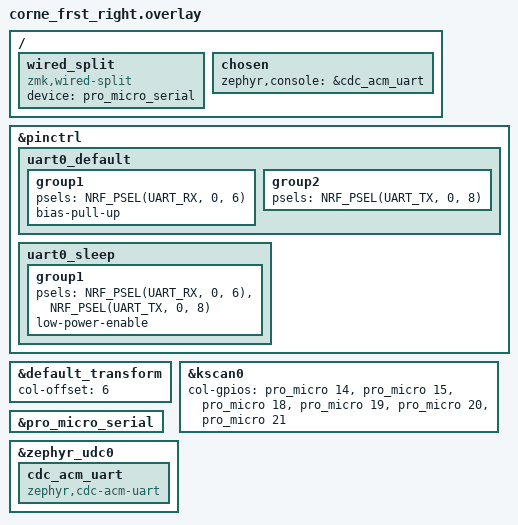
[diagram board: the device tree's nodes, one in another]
/*
 * Copyright (c) 2025 Jon Sharp
 * Co-authored by Claude (Anthropic)
 * SPDX-License-Identifier: MIT
 */

#include <dt-bindings/pinctrl/nrf-pinctrl.h>
#include "corne_frst.dtsi"

/*
 * Swap TX/RX pins on the right half for TRRS crossover.
 * Standard nice!nano: TX=P0.06, RX=P0.08
 * Swapped for right: TX=P0.08, RX=P0.06
 * This way straight TRRS cable crosses the signals properly.
 */
&pinctrl {
    uart0_default: uart0_default {
        group1 {
            psels = <NRF_PSEL(UART_RX, 0, 6)>;
            bias-pull-up;
        };
        group2 {
            psels = <NRF_PSEL(UART_TX, 0, 8)>;
        };
    };

    uart0_sleep: uart0_sleep {
        group1 {
            psels = <NRF_PSEL(UART_RX, 0, 6)>,
                <NRF_PSEL(UART_TX, 0, 8)>;
            low-power-enable;
        };
    };
};

/ {
    /* Wired split via TRRS cable using UART */
    wired_split {
        compatible = "zmk,wired-split";
        device = <&pro_micro_serial>;
    };
};

&default_transform {
    col-offset = <6>;
};

&kscan0 {
    col-gpios
        = <&pro_micro 14 GPIO_ACTIVE_HIGH>
        , <&pro_micro 15 GPIO_ACTIVE_HIGH>
        , <&pro_micro 18 GPIO_ACTIVE_HIGH>
        , <&pro_micro 19 GPIO_ACTIVE_HIGH>
        , <&pro_micro 20 GPIO_ACTIVE_HIGH>
        , <&pro_micro 21 GPIO_ACTIVE_HIGH>
        ;
};

&pro_micro_serial {
    status = "okay";
};

/*
 * USB CDC ACM console configuration (for debugging)
 */
/ {
    chosen {
        zephyr,console = &cdc_acm_uart;
    };
};

&zephyr_udc0 {
    cdc_acm_uart: cdc_acm_uart {
        compatible = "zephyr,cdc-acm-uart";
    };
};
